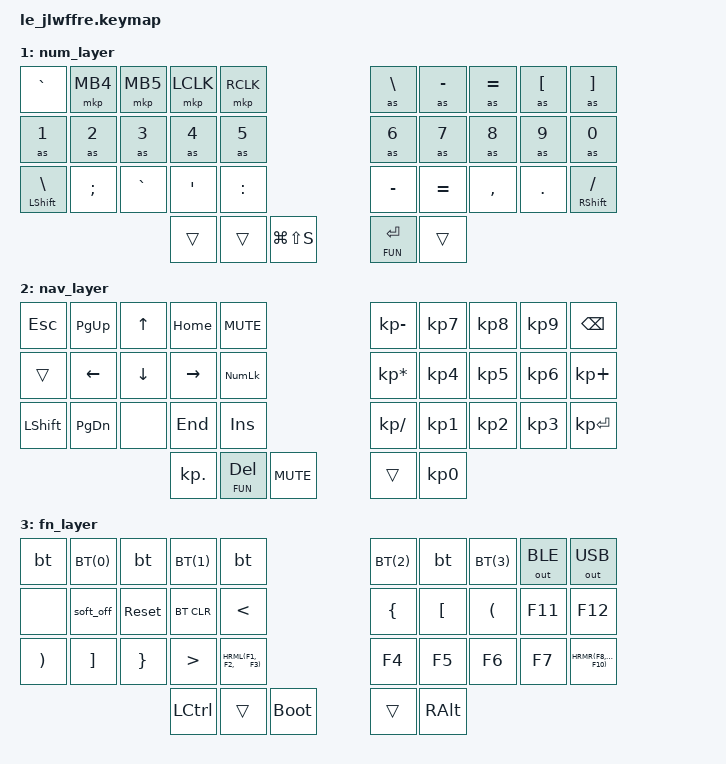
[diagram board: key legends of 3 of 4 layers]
/*
 * Copyright (c) 2022 The ZMK Contributors
 *
 * SPDX-License-Identifier: MIT
 */

#include <behaviors.dtsi>
#include <dt-bindings/zmk/keys.h>
#include <dt-bindings/zmk/bt.h>
#include <dt-bindings/zmk/outputs.h>
#include <dt-bindings/zmk/mouse.h>

// Layer defines
#define ALP 0
#define NUM 1
#define NAV 2
#define FUN 3

#define BT(n) BT_SEL n

// Home row mods macro
#define HRML(k1,k2,k3) &ht LSHFT k1 &ht LCTRL k2  &ht LALT k3
#define HRMR(k1,k2,k3) &ht RALT k1  &ht RCTRL k2  &ht RSHFT k3

// Soft Off keyboard use
&soft_off {
    hold-time-ms = <2000>; // Only turn off it the key is held for 5 seconds or longer.
};

/ {
    behaviors {
        ht: hold_tap {
            compatible = "zmk,behavior-hold-tap";
            #binding-cells = <2>;
            flavor = "balanced";
            tapping-term-ms = <200>;
            quick-tap-ms = <220>;
            require-prior-idle-ms = <125>;
            bindings = <&kp>, <&kp>;
        };
        mt: mod_tap {
            #binding-cells = <2>;
            tapping-term-ms = <200>;
            quick-tap-ms = <220>;
            require-prior-idle-ms = <125>;
            bindings = <&kp>, <&kp>;
        };
        as_ht: autoshift_hold_tap {
            compatible = "zmk,behavior-hold-tap";
            #binding-cells = <2>;
            tapping-term-ms = <200>;
            bindings = <&shifted>, <&kp>;
            flavor = "tap-preferred";
        };

        combos {
            compatible = "zmk,combos";
            combo_esc {
                timeout-ms = <50>;
                key-positions = <0 1>;
                bindings = <&kp ESC>;
            };
            combo_del {
                timeout-ms = <50>;
                key-positions = <8 9>;
                bindings = <&kp BSPC>;
            };
            combo_reset {
                timeout-ms = <50>;
                key-positions = <0 9>;
                layers = <3>;
                bindings = <&sys_reset>;
            };
            combo_boot {
                timeout-ms = <50>;
                key-positions = <4 18 24>;
                layers = <3>;
                bindings = <&bootloader>;
            };
        };
    };

    macros {
        shifted: macro_shifted_kp {
            #binding-cells = <1>;
            compatible = "zmk,behavior-macro-one-param";
            bindings =
              <&macro_press &kp LSHFT>,
              <&macro_param_1to1 &macro_tap &kp MACRO_PLACEHOLDER>,
              <&macro_release &kp LSHFT>;
        };
        as: autoshift {
            compatible = "zmk,behavior-macro-one-param";
            #binding-cells = <1>;
            bindings =
              <&macro_press>,
              <&macro_param_1to1>,
              <&macro_param_1to2>,
              <&as_ht MACRO_PLACEHOLDER MACRO_PLACEHOLDER>,
              <&macro_pause_for_release>,
              <&macro_release>,
              <&macro_param_1to1>,
              <&macro_param_1to2>,
              <&as_ht MACRO_PLACEHOLDER MACRO_PLACEHOLDER>;
        };
    };

    keymap {
        compatible = "zmk,keymap";
        default_layer { // ALP
            bindings = <
        //╭──────────┬──────────┬──────────┬──────────┬──────────╮                      ╭──────────┬──────────┬──────────┬──────────┬──────────╮
        //│  Q       │  W       │  F       │  P       │  B       │                      │  J       │  L       │  U       │  Y       │ ; :      │
            &kp Q      &kp W      &kp F      &kp P      &kp B                             &kp J      &kp L      &kp U      &kp Y      &lt NUM SEMI
        //├──────────┼──────────┼──────────┼──────────┼──────────┤                      ├──────────┼──────────┼──────────┼──────────┼──────────┤
        //│  A       │  R       │  S       │  T       │  G       │                      │  M       │  N       │  E       │  I       │ O        │
           &lt NAV A   &kp R      &kp S      &kp T      &kp G                             &kp M      &kp N      &kp E      &kp I      &kp O
        //├──────────┼──────────┼──────────┼──────────┼──────────┤                      ├──────────┼──────────┼──────────┼──────────┼──────────┤
        //│  Z       │  X       │  C       │  D       │  V       │                      │  K       │  H       │ , <      │ . >      │ / ?      │
        HRML(Z,         X,         C)        &kp D      &kp V                             &kp K      &kp H     HRMR(COMMA, DOT,      FSLH)
        //╰──────────┴──────────┴──────────┼──────────┼──────────┤                      ├──────────┼──────────┼──────────┴──────────┴──────────╯
                                            &mt LGUI SQT  &lt NUM BSPC  &kp LG(L)      &lt NAV SPACE &kp TAB
        //                                 ╰──────────┴──────────╯                      ╰──────────┴──────────╯
            >;
            sensor-bindings = <&inc_dec_kp LS(LC(TAB)) LC(TAB)>;
        };

        num_layer { // NUM
            bindings = <
        //╭──────────┬──────────┬──────────┬──────────┬──────────╮                ╭──────────┬──────────┬──────────┬──────────┬──────────╮
        //│  ` ~     │   BACK   │   FWD    │   BTN1   │   BTN2   │                │  \ |     │  - _     │  = +     │  [       │  ]       │
            &kp GRAVE  &mkp MB4   &mkp MB5   &mkp LCLK  &mkp RCLK                   &as BSLH   &as MINUS  &as EQUAL  &as LBKT   &as RBKT
        //├──────────┼──────────┼──────────┼──────────┼──────────┤                ├──────────┼──────────┼──────────┼──────────┼──────────┤
        //│  1 !     │  2 @     │  3 #     │  4 $     │  5 %     │                │  6 ^     │  7 &     │  8 *     │  9 (     │  0 )     │
            &as N1     &as N2     &as N3     &as N4     &as N5                      &as N6     &as N7     &as N8     &as N9     &as N0
        //├──────────┼──────────┼──────────┼──────────┼──────────┤                ├──────────┼──────────┼──────────┼──────────┼──────────┤
        //│          │          │          │          │          │                │          │          │          │          │          │
          &mt LSHFT BSLH  &kp SEMI &kp GRAVE  &kp SQT    &kp COLON                  &kp MINUS  &kp EQUAL  &kp COMMA  &kp DOT    &mt RSHFT FSLH
        //╰──────────┴──────────┴──────────┼──────────┼──────────┤                ├──────────┼──────────┼──────────┴──────────┴──────────╯
                                             &trans     &trans     &kp LG(LS(S))  &lt FUN ENTER  &trans
        //                                 ╰──────────┴──────────╯                ╰──────────┴──────────╯
            >;
            sensor-bindings = <&inc_dec_kp UP DOWN>;
        };

        nav_layer { // NAV
            bindings = <
        //╭──────────┬──────────┬──────────┬──────────┬──────────╮           ╭──────────┬──────────┬──────────┬──────────┬──────────╮
        //│          │ PG UP    │  UP      │ HOME     │          │           │  KP_-    │   KP_7   │   KP_8   │   KP_9   │  BSPACE  │
            &kp ESC    &kp PG_UP   &kp UP    &kp HOME   &kp C_MUTE         &kp KP_MINUS   &kp KP_N7  &kp KP_N8  &kp KP_N9  &kp BSPC
        //├──────────┼──────────┼──────────┼──────────┼──────────┤           ├──────────┼──────────┼──────────┼──────────┼──────────┤
        //│          │  LEFT    │  DOWN    │   RIGH   │          │           │  KP_*    │   KP_4   │   KP_5   │   KP_6   │  KP_+    │
            &trans     &kp LEFT   &kp DOWN   &kp RIGHT  &kp KP_NLCK       &kp KP_ASTERISK &kp KP_N4  &kp KP_N5  &kp KP_N6  &kp KP_PLUS
        //├──────────┼──────────┼──────────┼──────────┼──────────┤           ├──────────┼──────────┼──────────┼──────────┼──────────┤
        //│          │ PG DOWN  │          │  END     │          │           │  KP_DIV  │   KP_1   │   KP_2   │   KP_3   │  KP_ENT  │
            &kp LSHFT  &kp PG_DN  &none      &kp END    &kp INS            &kp KP_DIVIDE  &kp KP_N1  &kp KP_N2  &kp KP_N3  &kp KP_ENTER
        //╰──────────┴──────────┴──────────┼──────────┼──────────┤           ├──────────┼──────────┼──────────┴──────────┴──────────╯
                                           &kp KP_DOT  &lt FUN DEL &kp C_MUTE   &trans    &kp KP_N0
        //                                 ╰──────────┴──────────╯           ╰──────────┴──────────╯
            >;
            sensor-bindings = <&inc_dec_kp C_VOL_DN C_VOL_UP>;
        };

        fn_layer { // FUN
            bindings = <
        //╭──────────┬──────────┬──────────┬──────────┬──────────╮           ╭──────────┬──────────┬──────────┬──────────┬──────────╮
        //│          │          │          │          │          │           │          │          │          │          │          │
            &bt BT(0)   &bt BT(1)  &bt BT(2)  &bt BT(3) &out OUT_BLE          &out OUT_USB &none     &soft_off  &sys_reset  &bt BT_CLR
        //├──────────┼──────────┼──────────┼──────────┼──────────┤           ├──────────┼──────────┼──────────┼──────────┼──────────┤
        //│   <      │   {      │   [      │   (      │  F11     │           │  F12     │   )      │   ]      │   }      │    >     │
            &kp LT      &kp LBRC   &kp LBKT   &kp LPAR  &kp F11                &kp F12    &kp RPAR   &kp RBKT   &kp RBRC    &kp GT        
        //├──────────┼──────────┼──────────┼──────────┼──────────┤           ├──────────┼──────────┼──────────┼──────────┼──────────┤
        //│  F1      │  F2      │  F3      │  F4      │  F5      │           │  F6      │  F7      │  F8      │  F9      │  F10     │
            HRML(F1,    F2,        F3)       &kp F4     &kp F5                 &kp F6     &kp F7     HRMR(F8,    F9,        F10)
        //╰──────────┴──────────┴──────────┼──────────┼──────────┤           ├──────────┼──────────┼──────────┴──────────┴──────────╯
                                            &kp LCTRL   &trans    &bootloader   &trans     &kp RALT
        //                                 ╰──────────┴──────────╯           ╰──────────┴──────────╯
            >;
            sensor-bindings = <&inc_dec_kp LEFT RIGHT>;
        };

    };

};
